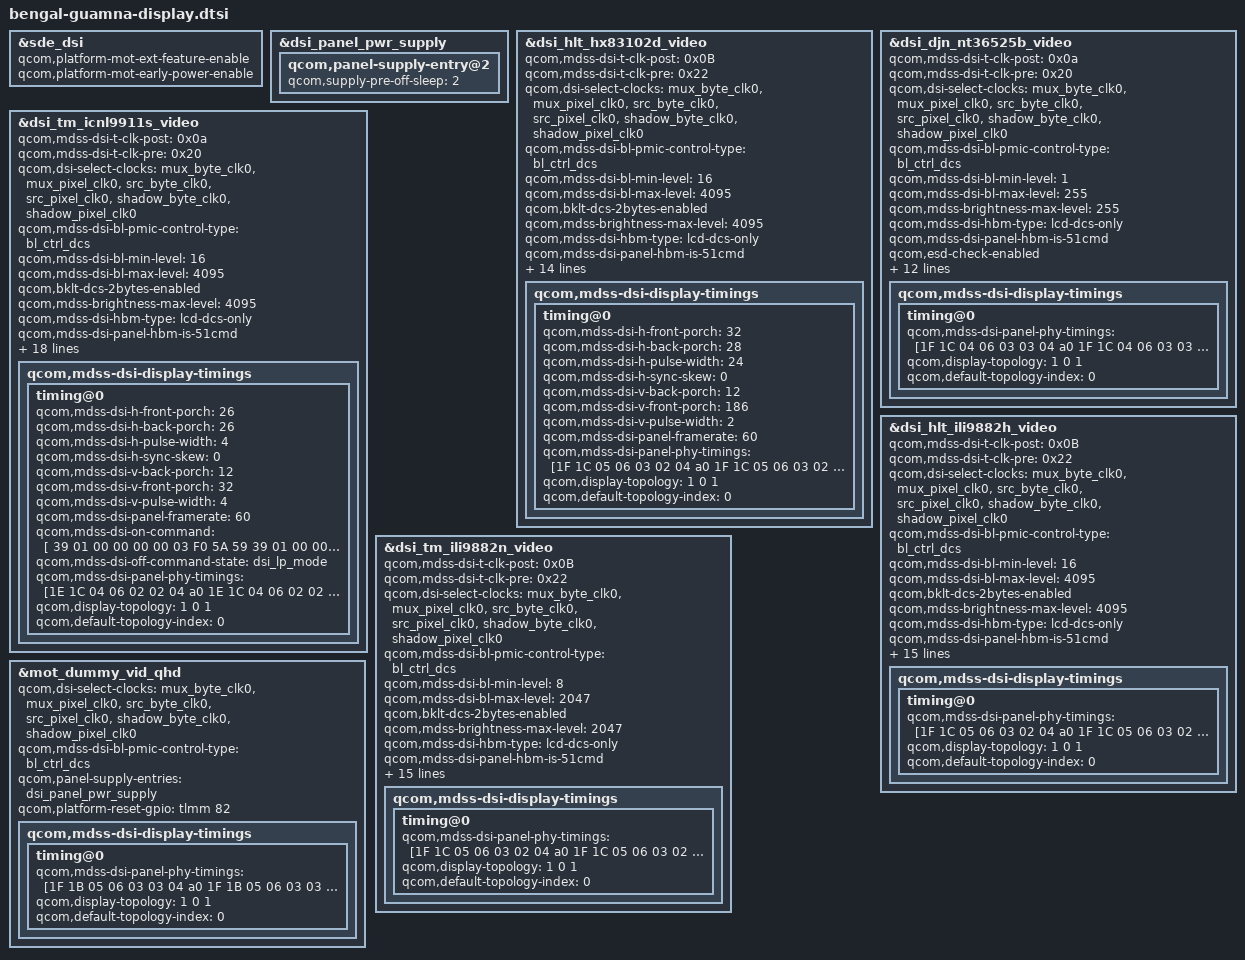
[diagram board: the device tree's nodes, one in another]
#include <dt-bindings/clock/mdss-14nm-pll-clk.h>
#include "bengal-sde-display.dtsi"
#include "dsi-panel-mot-dummy-qhd-video.dtsi"
#include "dsi-panel-moto-hx83102d-hlt-hdplus-video.dtsi"
#include "dsi-panel-moto-nt36525b-djn-hdplus-video.dtsi"
#include "dsi-panel-moto-icnl9911s-tm-hdplus-video.dtsi"
#include "dsi-panel-moto-ili9882h-hlt-hdplus-video.dtsi"
#include "dsi-panel-moto-ili9882n-tm-hdplus-video.dtsi"

&sde_dsi {
    qcom,platform-mot-ext-feature-enable;
    qcom,platform-mot-early-power-enable;
};

&dsi_panel_pwr_supply {
        qcom,panel-supply-entry@2 {
                qcom,supply-pre-off-sleep = <2>;
        };
};

&dsi_hlt_hx83102d_video {
	qcom,mdss-dsi-t-clk-post = <0x0B>;
	qcom,mdss-dsi-t-clk-pre = <0x22>;
	qcom,dsi-select-clocks = "mux_byte_clk0", "mux_pixel_clk0",
				"src_byte_clk0", "src_pixel_clk0",
				"shadow_byte_clk0", "shadow_pixel_clk0";

	qcom,mdss-dsi-bl-pmic-control-type = "bl_ctrl_dcs";
	qcom,mdss-dsi-bl-min-level = <16>;
	qcom,mdss-dsi-bl-max-level = <4095>;
	qcom,bklt-dcs-2bytes-enabled;
	qcom,mdss-brightness-max-level = <4095>;
	qcom,mdss-dsi-hbm-type = "lcd-dcs-only";
	qcom,mdss-dsi-panel-hbm-is-51cmd;

	qcom,esd-check-enabled;
	qcom,mdss-dsi-panel-status-check-mode = "reg_read";
	qcom,mdss-dsi-panel-status-command =[06 01 00 01 00 00 01 0a];
	qcom,mdss-dsi-panel-status-command-state = "dsi_lp_mode";
	qcom,mdss-dsi-panel-status-value = <0x9d>;
	qcom,mdss-dsi-panel-status-read-length = <4>;
	qcom,mdss-dsi-panel-status-valid-params = <1>;
	qcom,mdss-dsi-no-panel-on-read-support;

	qcom,panel-supply-entries = <&dsi_panel_pwr_supply>;
	qcom,platform-reset-gpio = <&tlmm 82 0>;

	qcom,mdss-dsi-display-timings {
		timing@0 {
			qcom,mdss-dsi-h-front-porch = <32>;
			qcom,mdss-dsi-h-back-porch = <28>;
			qcom,mdss-dsi-h-pulse-width = <24>;
			qcom,mdss-dsi-h-sync-skew = <0>;
			qcom,mdss-dsi-v-back-porch = <12>;
			qcom,mdss-dsi-v-front-porch = <186>;
			qcom,mdss-dsi-v-pulse-width = <2>;
			qcom,mdss-dsi-panel-framerate = <60>;

			qcom,mdss-dsi-panel-phy-timings =
				[1F 1C 05 06 03 02 04 a0
				1F 1C 05 06 03 02 04 a0
				1F 1C 05 06 03 02 04 a0
				1F 1C 05 06 03 02 04 a0
				1F 10 05 06 03 02 04 a0];
			qcom,display-topology = <1 0 1>;
			qcom,default-topology-index = <0>;
		};
	};
};

&dsi_djn_nt36525b_video {
	qcom,mdss-dsi-t-clk-post = <0x0a>;
	qcom,mdss-dsi-t-clk-pre = <0x20>;
	qcom,dsi-select-clocks = "mux_byte_clk0", "mux_pixel_clk0",
				"src_byte_clk0", "src_pixel_clk0",
				"shadow_byte_clk0", "shadow_pixel_clk0";

	qcom,mdss-dsi-bl-pmic-control-type = "bl_ctrl_dcs";
	qcom,mdss-dsi-bl-min-level = <1>;
	qcom,mdss-dsi-bl-max-level = <255>;
	//qcom,bklt-dcs-2bytes-enabled;
	qcom,mdss-brightness-max-level = <255>;
	qcom,mdss-dsi-hbm-type = "lcd-dcs-only";
	qcom,mdss-dsi-panel-hbm-is-51cmd;

	qcom,esd-check-enabled;
	qcom,mdss-dsi-panel-status-check-mode = "reg_read";
	qcom,mdss-dsi-panel-status-command =[06 01 00 01 00 00 01 0a];
	qcom,mdss-dsi-panel-status-command-state = "dsi_lp_mode";
	qcom,mdss-dsi-panel-status-value = <0x9c>;
	qcom,mdss-dsi-panel-status-read-length = <1>;
	qcom,mdss-dsi-no-panel-on-read-support;

	qcom,panel-supply-entries = <&dsi_panel_pwr_supply>;
	qcom,platform-reset-gpio = <&tlmm 82 0>;

	qcom,mdss-dsi-display-timings {
		timing@0 {
			qcom,mdss-dsi-panel-phy-timings =
				[1F 1C 04 06 03 03 04 a0
				1F 1C 04 06 03 03 04 a0
				1F 1C 04 06 03 03 04 a0
				1F 1C 04 06 03 03 04 a0
				1F 0F 04 06 03 03 04 a0];
			qcom,display-topology = <1 0 1>;
			qcom,default-topology-index = <0>;
		};
	};
};

&dsi_tm_icnl9911s_video {
	qcom,mdss-dsi-t-clk-post = <0x0a>;
	qcom,mdss-dsi-t-clk-pre = <0x20>;
	qcom,dsi-select-clocks = "mux_byte_clk0", "mux_pixel_clk0",
				"src_byte_clk0", "src_pixel_clk0",
				"shadow_byte_clk0", "shadow_pixel_clk0";

	qcom,mdss-dsi-bl-pmic-control-type = "bl_ctrl_dcs";
	qcom,mdss-dsi-bl-min-level = <16>;
	qcom,mdss-dsi-bl-max-level = <4095>;
	qcom,bklt-dcs-2bytes-enabled;
	qcom,mdss-brightness-max-level = <4095>;
	qcom,mdss-dsi-hbm-type = "lcd-dcs-only";
	qcom,mdss-dsi-panel-hbm-is-51cmd;

	qcom,esd-check-enabled;
	qcom,mdss-dsi-panel-status-check-mode = "reg_read";
	qcom,mdss-dsi-panel-status-command =[06 01 00 01 00 00 01 0a];
	qcom,mdss-dsi-panel-status-command-state = "dsi_lp_mode";
	qcom,mdss-dsi-panel-status-value = <0x9c>;
	qcom,mdss-dsi-panel-status-read-length = <1>;
	qcom,mdss-dsi-no-panel-on-read-support;
	qcom,platform-reset-gpio-always-on;

	qcom,mdss-dsi-cabc-dis-command-state = "dsi_lp_mode";
	qcom,mdss-dsi-hbm-off-command-state = "dsi_lp_mode";

	qcom,panel-supply-entries = <&dsi_panel_pwr_supply>;
	qcom,platform-reset-gpio = <&tlmm 82 0>;

	qcom,mdss-dsi-display-timings {
		timing@0 {
			qcom,mdss-dsi-h-front-porch = <26>;
			qcom,mdss-dsi-h-back-porch = <26>;
			qcom,mdss-dsi-h-pulse-width = <4>;
			qcom,mdss-dsi-h-sync-skew = <0>;
			qcom,mdss-dsi-v-back-porch = <12>;
			qcom,mdss-dsi-v-front-porch = <32>;
			qcom,mdss-dsi-v-pulse-width = <4>;
			qcom,mdss-dsi-panel-framerate = <60>;

			qcom,mdss-dsi-on-command = [
                                        39 01 00 00 00 00 03 F0 5A 59
                                        39 01 00 00 00 00 03 F1 A5 A6
                                        39 01 00 00 00 00 07 E0 30 A8 01 08 11 3F
                                        39 01 00 00 00 00 14 C1 C0 0C 20 78 04 1A 1A 04 2A 40 76 00 07 CF FF FF 9F 01 C0
                                        39 01 00 00 00 00 0B C6 89 15 22 29 29 33 64 24 08 04
                                        39 01 00 00 00 00 1B E0 30 A8 21 18 11 1F 02 62 DF A0 04 CC 00 FF F6 FF F0 FD FF FD F8 F5 FC FC FD FF
                                        39 01 00 00 00 00 15 E1 EF FE FE FE FE EE F0 20 33 FF 00 00 6A 90 C0 0D 6A F0 3E FF
                                        39 01 00 00 00 00 03 F1 5A 59
                                        39 01 00 00 00 00 03 F0 A5 A6
                                        15 01 00 00 00 00 02 35 00
                                        39 01 00 00 00 00 03 51 00 00
                                        15 01 00 00 00 00 02 53 2C
                                        15 01 00 00 00 00 02 55 01
                                        05 01 00 00 78 00 02 11 00
                                        05 01 00 00 14 00 02 29 00
                                        15 01 00 00 00 00 02 26 01];
			qcom,mdss-dsi-off-command-state = "dsi_lp_mode";

			qcom,mdss-dsi-panel-phy-timings =
				[1E 1C 04 06 02 02 04 a0
				1E 1C 04 06 02 02 04 a0
				1E 1C 04 06 02 02 04 a0
				1E 1C 04 06 02 02 04 a0
				1E 0E 04 05 02 02 04 a0];
			qcom,display-topology = <1 0 1>;
			qcom,default-topology-index = <0>;
		};
	};
};

&dsi_hlt_ili9882h_video {
	qcom,mdss-dsi-t-clk-post = <0x0B>;
	qcom,mdss-dsi-t-clk-pre = <0x22>;
	qcom,dsi-select-clocks = "mux_byte_clk0", "mux_pixel_clk0",
				"src_byte_clk0", "src_pixel_clk0",
				"shadow_byte_clk0", "shadow_pixel_clk0";

	qcom,mdss-dsi-bl-pmic-control-type = "bl_ctrl_dcs";
	qcom,mdss-dsi-bl-min-level = <16>;
	qcom,mdss-dsi-bl-max-level = <4095>;
	qcom,bklt-dcs-2bytes-enabled;
	qcom,mdss-brightness-max-level = <4095>;
	qcom,mdss-dsi-hbm-type = "lcd-dcs-only";
	qcom,mdss-dsi-panel-hbm-is-51cmd;

	qcom,esd-check-enabled;
	qcom,mdss-dsi-panel-status-check-mode = "reg_read";
	qcom,mdss-dsi-panel-status-command =[06 01 00 01 00 00 01 0a];
	qcom,mdss-dsi-panel-status-command-state = "dsi_lp_mode";
	qcom,mdss-dsi-panel-status-value = <0x9c>;
	qcom,mdss-dsi-panel-status-read-length = <4>;
	qcom,mdss-dsi-panel-status-valid-params = <1>;
	qcom,mdss-dsi-no-panel-on-read-support;

	qcom,tp_state_check_enable;

	qcom,panel-supply-entries = <&dsi_panel_pwr_supply>;
	qcom,platform-reset-gpio = <&tlmm 82 0>;

	qcom,mdss-dsi-display-timings {
		timing@0 {
		    qcom,mdss-dsi-panel-phy-timings =
		        [1F 1C 05 06 03 02 04 a0
		        1F 1C 05 06 03 02 04 a0
		        1F 1C 05 06 03 02 04 a0
		        1F 1C 05 06 03 02 04 a0
		        1F 10 05 06 03 02 04 a0];
		    qcom,display-topology = <1 0 1>;
		    qcom,default-topology-index = <0>;
		};
	};
};

&dsi_tm_ili9882n_video {
	qcom,mdss-dsi-t-clk-post = <0x0B>;
	qcom,mdss-dsi-t-clk-pre = <0x22>;
	qcom,dsi-select-clocks = "mux_byte_clk0", "mux_pixel_clk0",
				"src_byte_clk0", "src_pixel_clk0",
				"shadow_byte_clk0", "shadow_pixel_clk0";

	qcom,mdss-dsi-bl-pmic-control-type = "bl_ctrl_dcs";
	qcom,mdss-dsi-bl-min-level = <8>;
	qcom,mdss-dsi-bl-max-level = <2047>;
	qcom,bklt-dcs-2bytes-enabled;
	qcom,mdss-brightness-max-level = <2047>;
	qcom,mdss-dsi-hbm-type = "lcd-dcs-only";
	qcom,mdss-dsi-panel-hbm-is-51cmd;

	qcom,esd-check-enabled;
	qcom,mdss-dsi-panel-status-check-mode = "reg_read";
	qcom,mdss-dsi-panel-status-command =[06 01 00 01 00 00 01 0a];
	qcom,mdss-dsi-panel-status-command-state = "dsi_lp_mode";
	qcom,mdss-dsi-panel-status-value = <0x9c>;
	qcom,mdss-dsi-panel-status-read-length = <4>;
	qcom,mdss-dsi-panel-status-valid-params = <1>;
	qcom,mdss-dsi-no-panel-on-read-support;
	qcom,platform-reset-gpio-always-on;

	qcom,panel-supply-entries = <&dsi_panel_pwr_supply>;
	qcom,platform-reset-gpio = <&tlmm 82 0>;

	qcom,mdss-dsi-display-timings {
		timing@0 {
		    qcom,mdss-dsi-panel-phy-timings =
		        [1F 1C 05 06 03 02 04 a0
		        1F 1C 05 06 03 02 04 a0
		        1F 1C 05 06 03 02 04 a0
		        1F 1C 05 06 03 02 04 a0
		        1F 10 05 06 03 02 04 a0];
		    qcom,display-topology = <1 0 1>;
		    qcom,default-topology-index = <0>;
		};
	};
};

&mot_dummy_vid_qhd {
	qcom,dsi-select-clocks = "mux_byte_clk0", "mux_pixel_clk0",
				"src_byte_clk0", "src_pixel_clk0",
				"shadow_byte_clk0", "shadow_pixel_clk0";

	qcom,mdss-dsi-bl-pmic-control-type = "bl_ctrl_dcs";
	qcom,panel-supply-entries = <&dsi_panel_pwr_supply>;
	qcom,platform-reset-gpio = <&tlmm 82 0>;

	qcom,mdss-dsi-display-timings {
		timing@0 {
			qcom,mdss-dsi-panel-phy-timings =
				[1F 1B 05 06 03 03 04 a0
				1F 1B 05 06 03 03 04 a0
				1F 1B 05 06 03 03 04 a0
				1F 1B 05 06 03 03 04 a0
				1F 10 04 06 03 03 04 a0];
			qcom,display-topology = <1 0 1>;
			qcom,default-topology-index = <0>;
		};
	};
};
